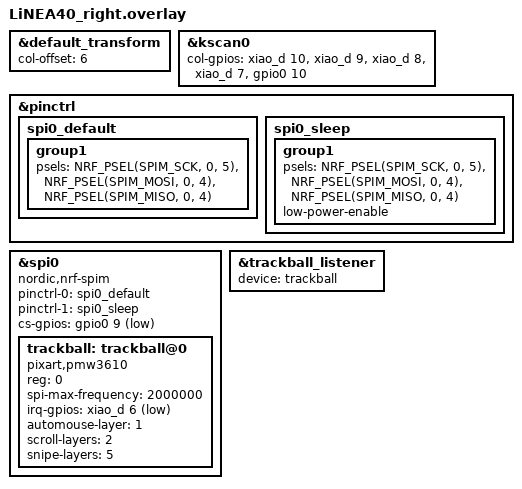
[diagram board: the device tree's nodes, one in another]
#include "LiNEA40.dtsi"
&default_transform {
    col-offset = <6>;
};

&kscan0 {
    col-gpios
        = <&xiao_d 10 GPIO_ACTIVE_HIGH> //col0-D10
        , <&xiao_d 9 GPIO_ACTIVE_HIGH>  //col1-D9
        , <&xiao_d 8 GPIO_ACTIVE_HIGH>  //col2-D8
        , <&xiao_d 7 GPIO_ACTIVE_HIGH>  //col3-D7
        , <&gpio0 10 GPIO_ACTIVE_HIGH>  //col4-NFC2
        ;
};

&pinctrl {
    spi0_default: spi0_default {
        group1 {
            psels = <NRF_PSEL(SPIM_SCK, 0, 5)>   // SCLK-D5
                  , <NRF_PSEL(SPIM_MOSI, 0, 4)>  // SDIO-D4
                  , <NRF_PSEL(SPIM_MISO, 0, 4)>  // SDIO-D4
                  ;
        };
    };

    spi0_sleep: spi0_sleep {
        group1 {
            psels = <NRF_PSEL(SPIM_SCK, 0, 5)>   // SCLK-D5
                  , <NRF_PSEL(SPIM_MOSI, 0, 4)>  // SDIO-D4
                  , <NRF_PSEL(SPIM_MISO, 0, 4)>  // SDIO-D4
                  ;
            low-power-enable;
        };
    };
};

&spi0 {
    status = "okay";
    compatible = "nordic,nrf-spim";
    pinctrl-0 = <&spi0_default>;
    pinctrl-1 = <&spi0_sleep>;
    pinctrl-names = "default", "sleep";
    cs-gpios = <&gpio0 9 GPIO_ACTIVE_LOW>; //NCS-NFC1

    trackball: trackball@0 {
        status = "okay";
        compatible = "pixart,pmw3610";
        reg = <0>;
        spi-max-frequency = <2000000>;
        irq-gpios = <&xiao_d 6 (GPIO_ACTIVE_LOW | GPIO_PULL_UP)>; //MOT-D6
        // Layer numbers must match the #defines in config/LiNEA40.keymap
        automouse-layer = <1>;  // L_MOUSE
        scroll-layers = <2>;    // L_NAV   -- the left thumb holds it, so the right hand is free for the ball
        snipe-layers = <5>;     // L_SNIPE -- held from the Mouse layer
    };
};

/* The node itself is declared disabled in LiNEA40.dtsi; this is the only place
 * that enables it and points it at the sensor. There used to be a second
 * declaration of the same node higher up in this file, setting the same two
 * properties -- harmless, but it meant an edit up there would be silently
 * overridden down here, and deleting this block would have left the listener
 * disabled with nothing to say so. */
&trackball_listener {
    status = "okay";
    device = <&trackball>;
};
